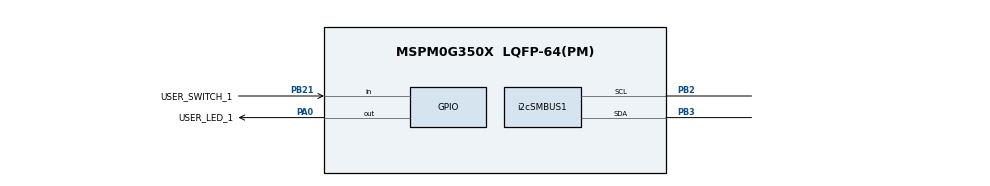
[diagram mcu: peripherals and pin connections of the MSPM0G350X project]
// @cliArgs --device "MSPM0G350X" --package "LQFP-64(PM)" --part "Default"
// @cliArgs --board /ti/boards/LP_MSPM0G3507 --rtos nortos

/**
 * Import the modules used in this configuration.
 */
const GPIO          = scripting.addModule("/ti/driverlib/GPIO", {}, false);
const GPIO1         = GPIO.addInstance();
const GPIO2         = GPIO.addInstance();
const SYSCTL        = scripting.addModule("/ti/driverlib/SYSCTL");
const i2cSMBUS      = scripting.addModule("/ti/driverlib/i2cSMBUS", {}, false);
const i2cSMBUS1     = i2cSMBUS.addInstance();
const ProjectConfig = scripting.addModule("/ti/project_config/ProjectConfig");

/**
 * Write custom configuration values to the imported modules.
 */
GPIO1.$name                                 = "GPIO_LEDS";
GPIO1.associatedPins[0].assignedPort        = "PORTA";
GPIO1.associatedPins[0].assignedPortSegment = "Lower";
GPIO1.associatedPins[0].assignedPin         = "0";
GPIO1.associatedPins[0].$name               = "USER_LED_1";
GPIO1.associatedPins[0].initialValue        = "SET";
GPIO1.associatedPins[0].pin.$assign         = "PA0";

const Board = scripting.addModule("/ti/driverlib/Board", {}, false);

GPIO2.$name                              = "GPIO_SWITCHES";
GPIO2.associatedPins[0].$name            = "USER_SWITCH_1";
GPIO2.associatedPins[0].direction        = "INPUT";
GPIO2.associatedPins[0].assignedPort     = "PORTB";
GPIO2.associatedPins[0].assignedPin      = "21";
GPIO2.associatedPins[0].internalResistor = "PULL_UP";
GPIO2.associatedPins[0].interruptEn      = true;
GPIO2.associatedPins[0].polarity         = "FALL";
GPIO2.associatedPins[0].pin.$assign      = "PB21";

SYSCTL.peripheral.$assign = "SYSCTL";

i2cSMBUS1.basicEnableController             = true;
i2cSMBUS1.$name                             = "SMB_I2C";
i2cSMBUS1.enableTimeoutA                    = true;
i2cSMBUS1.timeoutACount                     = 255;
i2cSMBUS1.intGeneric                        = ["TIMEOUT_A"];
i2cSMBUS1.enableControllerPEC               = true;
i2cSMBUS1.basicEnableTarget                 = true;
i2cSMBUS1.enableDefaultHostAddr             = true;
i2cSMBUS1.intTarget                         = ["RXFIFO_TRIGGER","START","STOP","TXFIFO_EMPTY"];
i2cSMBUS1.advTargetTXEmptyEn                = true;
i2cSMBUS1.advControllerMultiController      = true;
i2cSMBUS1.basicTargetOwnAddressEnable       = false;
i2cSMBUS1.intController                     = ["ARBITRATION_LOST","NACK","PEC_RX_ERROR","RXFIFO_TRIGGER","START","STOP"];
i2cSMBUS1.peripheral.$assign                = "I2C1";
i2cSMBUS1.peripheral.sdaPin.$assign         = "PB3";
i2cSMBUS1.peripheral.sclPin.$assign         = "PB2";

ProjectConfig.genLibSMBUS = true;
